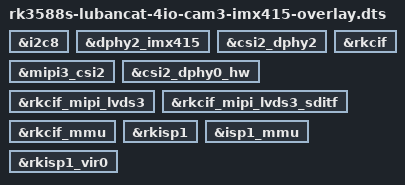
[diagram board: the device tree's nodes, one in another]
/dts-v1/;
/plugin/;

#include <dt-bindings/usb/pd.h>
#include <dt-bindings/gpio/gpio.h>
#include <dt-bindings/pwm/pwm.h>
#include <dt-bindings/pinctrl/rockchip.h>
#include <dt-bindings/input/rk-input.h>
#include <dt-bindings/display/drm_mipi_dsi.h>
#include <dt-bindings/display/rockchip_vop.h>
#include <dt-bindings/sensor-dev.h>

/ {
/* Link path:
 * sensor->csi2_dphy2->mipi3_csi2->rkcif_mipi_lvds3->rkcif_mipi_lvds3_sditf->rkisp1_vir0
 */
	fragment@0 {
		target = <&i2c8>;
		__overlay__ {
			status = "okay";
		};
	};

	fragment@1 {
		target = <&dphy2_imx415>;
		__overlay__ {
			status = "okay";
		};
	};

	fragment@2 {
		target = <&csi2_dphy2>;

		__overlay__ {
			status = "okay";
		};
	};

	fragment@3 {
		target = <&mipi3_csi2>;

		__overlay__ {
			status = "okay";
		};
	};

	fragment@4 {
		target = <&csi2_dphy0_hw>;

		__overlay__ {
			status = "okay";
		};
	};

	fragment@5 {
		target = <&rkcif>;

		__overlay__ {
			status = "okay";
		};
	};

	fragment@6 {
		target = <&rkcif_mipi_lvds3>;

		__overlay__ {
			status = "okay";
		};
	};

	fragment@7 {
		target = <&rkcif_mipi_lvds3_sditf>;

		__overlay__ {
			status = "okay";
		};
	};

	fragment@8 {
		target = <&rkcif_mmu>;

		__overlay__ {
			status = "okay";
		};
	};

	fragment@9 {
		target = <&rkisp1>;

		__overlay__ {
			status = "okay";
		};
	};

	fragment@10 {
		target = <&isp1_mmu>;

		__overlay__ {
			status = "okay";
		};
	};

	fragment@11 {
		target = <&rkisp1_vir0>;

		__overlay__ {
			status = "okay";
		};
	};
};

